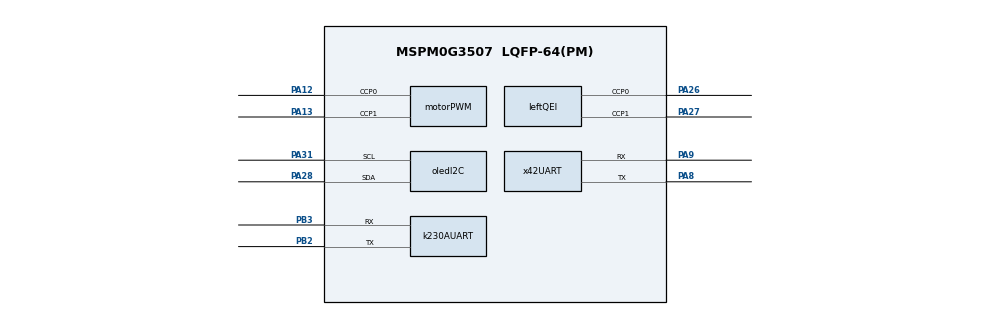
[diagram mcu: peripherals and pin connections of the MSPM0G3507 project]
/** MSPM0G3507 line-following car configuration. */
//@cliArgs --device "MSPM0G350X" --package "LQFP-64(PM)" --part "Default"
//@v2CliArgs --device "MSPM0G3507" --package "LQFP-64(PM)"

const SYSCTL = scripting.addModule("/ti/driverlib/SYSCTL");
const GPIO = scripting.addModule("/ti/driverlib/GPIO", {}, false);
const carGPIO = GPIO.addInstance();
const PWM = scripting.addModule("/ti/driverlib/PWM", {}, false);
const motorPWM = PWM.addInstance();
const QEI = scripting.addModule("/ti/driverlib/QEI", {}, false);
const leftQEI = QEI.addInstance();
const TIMER = scripting.addModule("/ti/driverlib/TIMER", {}, false);
const controlTimer = TIMER.addInstance();
const I2C = scripting.addModule("/ti/driverlib/I2C", {}, false);
const oledI2C = I2C.addInstance();
const UART = scripting.addModule("/ti/driverlib/UART", {}, false);
const x42UART = UART.addInstance();
const k230AUART = UART.addInstance();
const Board = scripting.addModule("/ti/driverlib/Board", {}, false);

SYSCTL.forceDefaultClkConfig = true;
SYSCTL.clockTreeEn = true;
Board.configureUnused = false;

carGPIO.$name = "CAR_GPIO";
carGPIO.associatedPins.create(18);

const motorPins = [
    ["MOTOR_AIN1", "PORTB", "17"],
    ["MOTOR_AIN2", "PORTB", "19"],
    ["MOTOR_BIN2", "PORTA", "16"],
    ["MOTOR_BIN1", "PORTB", "24"]
];
for (let i = 0; i < motorPins.length; ++i) {
    const pin = carGPIO.associatedPins[i];
    pin.$name = motorPins[i][0];
    pin.assignedPort = motorPins[i][1];
    pin.assignedPin = motorPins[i][2];
    pin.initialValue = "SET";
}

const keyPins = [
    ["KEY1", "PORTA", "15"],
    ["KEY2", "PORTB", "27"],
    ["KEY3", "PORTB", "23"],
    ["KEY4", "PORTA", "29"]
];
for (let i = 0; i < keyPins.length; ++i) {
    const pin = carGPIO.associatedPins[4 + i];
    pin.$name = keyPins[i][0];
    pin.assignedPort = keyPins[i][1];
    pin.assignedPin = keyPins[i][2];
    pin.direction = "INPUT";
    pin.internalResistor = "PULL_UP";
}

const grayPins = [
    ["GRAY_X0", "PORTB", "20"],
    ["GRAY_X1", "PORTA", "24"],
    ["GRAY_X2", "PORTB", "25"],
    ["GRAY_X3", "PORTB", "26"],
    ["GRAY_X4", "PORTB", "10"],
    ["GRAY_X5", "PORTB", "14"],
    ["GRAY_X6", "PORTA", "17"],
    ["GRAY_X7", "PORTA", "7"]
];
for (let i = 0; i < grayPins.length; ++i) {
    const pin = carGPIO.associatedPins[8 + i];
    pin.$name = grayPins[i][0];
    pin.assignedPort = grayPins[i][1];
    pin.assignedPin = grayPins[i][2];
    pin.direction = "INPUT";
}

carGPIO.associatedPins[16].$name = "RIGHT_ENCODER_A";
carGPIO.associatedPins[16].assignedPort = "PORTA";
carGPIO.associatedPins[16].assignedPin = "14";
carGPIO.associatedPins[16].direction = "INPUT";
carGPIO.associatedPins[16].interruptEn = true;
carGPIO.associatedPins[16].polarity = "RISE_FALL";
carGPIO.associatedPins[17].$name = "RIGHT_ENCODER_B";
carGPIO.associatedPins[17].assignedPort = "PORTA";
carGPIO.associatedPins[17].assignedPin = "25";
carGPIO.associatedPins[17].direction = "INPUT";
carGPIO.associatedPins[17].interruptEn = true;
carGPIO.associatedPins[17].polarity = "RISE_FALL";

motorPWM.$name = "MOTOR_PWM";
motorPWM.clockPrescale = 1;
motorPWM.timerCount = 1600;
motorPWM.peripheral.$assign = "TIMG0";
motorPWM.peripheral.ccp0Pin.$assign = "PA12";
motorPWM.peripheral.ccp1Pin.$assign = "PA13";
motorPWM.PWM_CHANNEL_0.$name = "LEFT_PWM";
motorPWM.PWM_CHANNEL_0.dutyCycle = 100;
motorPWM.PWM_CHANNEL_0.ccValue = 0;
motorPWM.PWM_CHANNEL_1.$name = "RIGHT_PWM";
motorPWM.PWM_CHANNEL_1.dutyCycle = 100;
motorPWM.PWM_CHANNEL_1.ccValue = 0;

leftQEI.$name = "LEFT_QEI";
leftQEI.peripheral.$assign = "TIMG8";
leftQEI.peripheral.ccp0Pin.$assign = "PA26";
leftQEI.peripheral.ccp1Pin.$assign = "PA27";

controlTimer.$name = "CONTROL_TIMER";
controlTimer.profile = "Basic_Periodic";
controlTimer.timerPeriod = "10 ms";
controlTimer.peripheral.$assign = "TIMG6";

oledI2C.$name = "OLED_I2C";
oledI2C.basicEnableController = true;
oledI2C.basicControllerBusSpeed = 400000;
oledI2C.peripheral.$assign = "I2C0";
oledI2C.peripheral.sdaPin.$assign = "PA28";
oledI2C.peripheral.sclPin.$assign = "PA31";

x42UART.$name = "X42_UART";
x42UART.targetBaudRate = 115200;
x42UART.enableFIFO = false;
x42UART.enabledInterrupts = ["RX"];
x42UART.peripheral.$assign = "UART1";
x42UART.peripheral.txPin.$assign = "PA8";
x42UART.peripheral.rxPin.$assign = "PA9";

k230AUART.$name = "K230_A_UART";
k230AUART.targetBaudRate = 115200;
k230AUART.enableFIFO = false;
k230AUART.enabledInterrupts = ["RX"];
k230AUART.peripheral.$assign = "UART3";
k230AUART.peripheral.txPin.$assign = "PB2";
k230AUART.peripheral.rxPin.$assign = "PB3";
